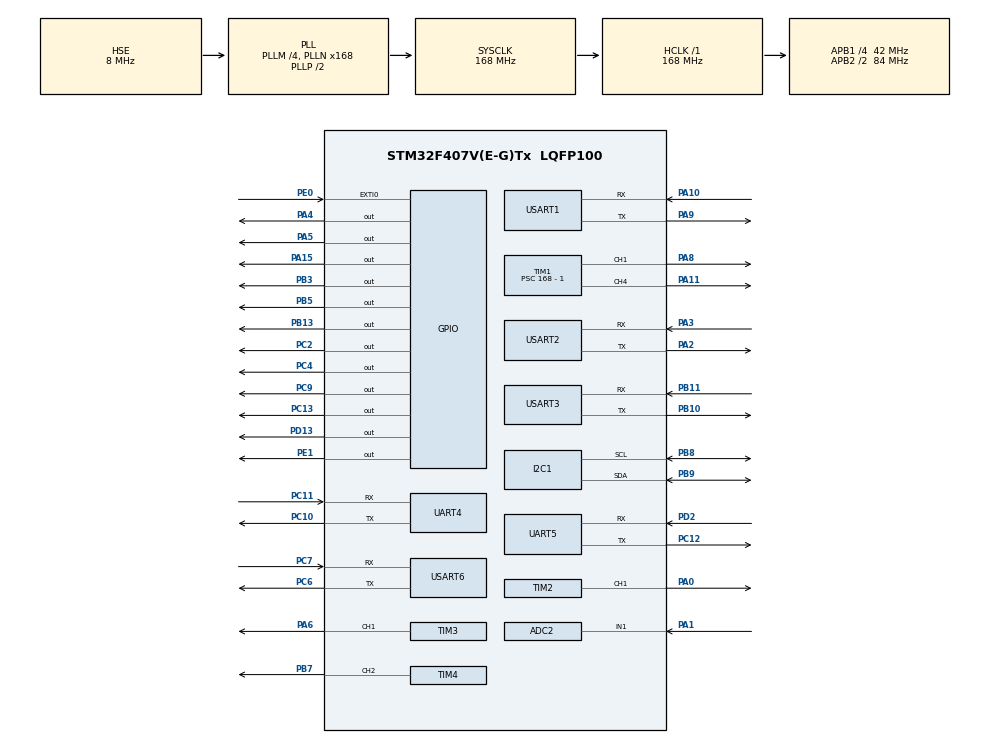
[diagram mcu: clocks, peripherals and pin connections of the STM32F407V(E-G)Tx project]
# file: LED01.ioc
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ADC2.Channel-0\#ChannelRegularConversion=ADC_CHANNEL_1
ADC2.NbrOfConversionFlag=1
ADC2.Rank-0\#ChannelRegularConversion=1
ADC2.SamplingTime-0\#ChannelRegularConversion=ADC_SAMPLETIME_3CYCLES
FREERTOS.BinarySemaphores01=KeySemaphore,Dynamic,NULL,Depleted
FREERTOS.Queues01=LEDQueue,16,LEDMessage*,0,Dynamic,NULL,NULL;CommandQueue,16,uint16_t,0,Dynamic,NULL,NULL;OLEDQueue,16,OLEDMessage*,0,Dynamic,NULL,NULL;TlyQueue,16,TlyMessage,0,Dynamic,NULL,NULL;DeepSensorQueue,16,DeepSensorMessage,0,Dynamic,NULL,NULL
FREERTOS.Tasks01=KeyTask,40,128,StartKeyTask,As weak,NULL,Dynamic,NULL,NULL;LEDTask,16,128,StartLEDTask,As external,NULL,Dynamic,NULL,NULL;CommandTask,41,128,StartCommandTask,As external,NULL,Dynamic,NULL,NULL;OLEDTask,8,256,StartOLEDTask,As external,NULL,Dynamic,NULL,NULL;TlyTask,25,128,StartTlyTask,As external,NULL,Dynamic,NULL,NULL;DeepSensorTask,16,128,StartDeepSensorTask,As external,NULL,Dynamic,NULL,NULL
Mcu.Family=STM32F4
Mcu.Name=STM32F407V(E-G)Tx
Mcu.Package=LQFP100
NVIC.EXTI0_IRQn=true\:5\:0\:false\:false\:true\:true\:true\:true\:true
NVIC.I2C1_ER_IRQn=true\:5\:0\:false\:false\:true\:true\:true\:true\:true
NVIC.I2C1_EV_IRQn=true\:5\:0\:false\:false\:true\:true\:true\:true\:true
NVIC.PriorityGroup=NVIC_PRIORITYGROUP_4
NVIC.TIM6_DAC_IRQn=true\:5\:0\:false\:false\:true\:false\:true\:true\:true
NVIC.TIM7_IRQn=true\:5\:0\:true\:false\:true\:false\:false\:true\:true
NVIC.TimeBase=TIM7_IRQn
NVIC.TimeBaseIP=TIM7
NVIC.UART4_IRQn=true\:5\:0\:false\:false\:true\:true\:true\:true\:true
NVIC.UART5_IRQn=true\:5\:0\:false\:false\:true\:true\:true\:true\:true
NVIC.USART1_IRQn=true\:5\:0\:false\:false\:true\:true\:true\:true\:true
NVIC.USART2_IRQn=true\:5\:0\:false\:false\:true\:true\:true\:true\:true
NVIC.USART3_IRQn=true\:5\:0\:false\:false\:true\:true\:true\:true\:true
NVIC.USART6_IRQn=true\:5\:0\:false\:false\:true\:true\:true\:true\:true
PA0-WKUP.Signal=S_TIM2_CH1_ETR
PA1.Signal=ADCx_IN1
PA10.Mode=Asynchronous
PA10.Signal=USART1_RX
PA11.Signal=S_TIM1_CH4
PA13.Mode=Serial_Wire
PA13.Signal=SYS_JTMS-SWDIO
PA14.Mode=Serial_Wire
PA14.Signal=SYS_JTCK-SWCLK
PA15.Signal=GPIO_Output
PA2.Mode=Asynchronous
PA2.Signal=USART2_TX
PA3.Mode=Asynchronous
PA3.Signal=USART2_RX
PA4.Signal=GPIO_Output
PA5.Signal=GPIO_Output
PA6.Signal=S_TIM3_CH1
PA8.Signal=S_TIM1_CH1
PA9.Mode=Asynchronous
PA9.Signal=USART1_TX
PB10.Mode=Asynchronous
PB10.Signal=USART3_TX
PB11.Mode=Asynchronous
PB11.Signal=USART3_RX
PB13.Signal=GPIO_Output
PB3.Signal=GPIO_Output
PB5.Signal=GPIO_Output
PB7.Signal=S_TIM4_CH2
PB8.Mode=I2C
PB8.Signal=I2C1_SCL
PB9.Mode=I2C
PB9.Signal=I2C1_SDA
PC10.Mode=Asynchronous
PC10.Signal=UART4_TX
PC11.Mode=Asynchronous
PC11.Signal=UART4_RX
PC12.Mode=Asynchronous
PC12.Signal=UART5_TX
PC13-ANTI_TAMP.Signal=GPIO_Output
PC2.Signal=GPIO_Output
PC4.Signal=GPIO_Output
PC6.Mode=Asynchronous
PC6.Signal=USART6_TX
PC7.Mode=Asynchronous
PC7.Signal=USART6_RX
PC9.Signal=GPIO_Output
PD13.Signal=GPIO_Output
PD2.Mode=Asynchronous
PD2.Signal=UART5_RX
PE0.GPIO_ModeDefaultEXTI=GPIO_MODE_IT_FALLING
PE0.Signal=GPXTI0
PE1.Signal=GPIO_Output
PH0-OSC_IN.Mode=HSE-External-Oscillator
PH0-OSC_IN.Signal=RCC_OSC_IN
PH1-OSC_OUT.Mode=HSE-External-Oscillator
PH1-OSC_OUT.Signal=RCC_OSC_OUT
ProjectManager.HeapSize=0x200
ProjectManager.StackSize=0x400
ProjectManager.TargetToolchain=CMake
RCC.48MHZClocksFreq_Value=84000000
RCC.AHBFreq_Value=168000000
RCC.APB1CLKDivider=RCC_HCLK_DIV4
RCC.APB1Freq_Value=42000000
RCC.APB1TimFreq_Value=84000000
RCC.APB2CLKDivider=RCC_HCLK_DIV2
RCC.APB2Freq_Value=84000000
RCC.APB2TimFreq_Value=168000000
RCC.CortexFreq_Value=168000000
RCC.HCLKFreq_Value=168000000
RCC.HSE_VALUE=8000000
RCC.HSI_VALUE=16000000
RCC.LSE_VALUE=32768
RCC.PLLM=4
RCC.PLLN=168
RCC.PLLSourceVirtual=RCC_PLLSOURCE_HSE
RCC.SYSCLKFreq_VALUE=168000000
RCC.SYSCLKSource=RCC_SYSCLKSOURCE_PLLCLK
RCC.VCOOutputFreq_Value=336000000
SH.ADCx_IN1.0=ADC2_IN1,IN1
SH.S_TIM1_CH1.0=TIM1_CH1,PWM Generation1 CH1
SH.S_TIM1_CH4.0=TIM1_CH4,PWM Generation4 CH4
SH.S_TIM2_CH1_ETR.0=TIM2_CH1,PWM Generation1 CH1
SH.S_TIM3_CH1.0=TIM3_CH1,PWM Generation1 CH1
SH.S_TIM4_CH2.0=TIM4_CH2,PWM Generation2 CH2
TIM1.AutoReloadPreload=TIM_AUTORELOAD_PRELOAD_ENABLE
TIM1.Channel-PWM\ Generation1\ CH1=TIM_CHANNEL_1
TIM1.Channel-PWM\ Generation4\ CH4=TIM_CHANNEL_4
TIM1.Period=500 - 1
TIM1.Prescaler=168 - 1
TIM2.AutoReloadPreload=TIM_AUTORELOAD_PRELOAD_ENABLE
TIM2.Channel-PWM\ Generation1\ CH1=TIM_CHANNEL_1
TIM2.Period=500 - 1
TIM2.Prescaler=84 - 1
TIM3.AutoReloadPreload=TIM_AUTORELOAD_PRELOAD_ENABLE
TIM3.Channel-PWM\ Generation1\ CH1=TIM_CHANNEL_1
TIM3.Period=500 - 1
TIM3.Prescaler=84 - 1
TIM4.AutoReloadPreload=TIM_AUTORELOAD_PRELOAD_ENABLE
TIM4.Channel-PWM\ Generation2\ CH2=TIM_CHANNEL_2
TIM4.Period=500 - 1
TIM4.Prescaler=84 - 1
TIM6.AutoReloadPreload=TIM_AUTORELOAD_PRELOAD_ENABLE
TIM6.Period=10000 - 1
TIM6.Prescaler=84 - 1
UART4.VirtualMode=Asynchronous
UART5.VirtualMode=Asynchronous
USART1.VirtualMode=VM_ASYNC
USART2.VirtualMode=VM_ASYNC
USART3.VirtualMode=VM_ASYNC
USART6.VirtualMode=VM_ASYNC
VP_FREERTOS_VS_CMSIS_V2.Mode=CMSIS_V2
VP_SYS_VS_tim7.Mode=TIM7
VP_TIM1_VS_ClockSourceINT.Mode=Internal
VP_TIM2_VS_ClockSourceINT.Mode=Internal
VP_TIM3_VS_ClockSourceINT.Mode=Internal
VP_TIM4_VS_ClockSourceINT.Mode=Internal
VP_TIM6_VS_ClockSourceINT.Mode=Enable_Timer
board=custom

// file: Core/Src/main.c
/* USER CODE BEGIN Header */
/**
  ******************************************************************************
  * @file           : main.c
  * @brief          : Main program body
  ******************************************************************************
  * @attention
  *
  * Copyright (c) 2026 STMicroelectronics.
  * All rights reserved.
  *
  * This software is licensed under terms that can be found in the LICENSE file
  * in the root directory of this software component.
  * If no LICENSE file comes with this software, it is provided AS-IS.
  *
  ******************************************************************************
  */
/* USER CODE END Header */
#include "main.h"
#include "cmsis_os.h"
#include "adc.h"
#include "i2c.h"
#include "tim.h"
#include "usart.h"
#include "gpio.h"

/* USER CODE BEGIN Includes */
#include "system.h"
/* USER CODE END Includes */

void SystemClock_Config(void);
void MX_FREERTOS_Init(void);

int main(void)
{

  /* MCU Configuration--------------------------------------------------------*/

  /* Reset of all peripherals, Initializes the Flash interface and the Systick. */
  HAL_Init();

  /* Configure the system clock */
  SystemClock_Config();

  /* Initialize all configured peripherals */
  MX_GPIO_Init();
  MX_TIM6_Init();
  MX_UART4_Init();
  MX_UART5_Init();
  MX_USART1_UART_Init();
  MX_USART2_UART_Init();
  MX_USART3_UART_Init();
  MX_USART6_UART_Init();
  MX_ADC2_Init();
  MX_TIM1_Init();
  MX_TIM2_Init();
  MX_TIM3_Init();
  MX_TIM4_Init();
  MX_I2C1_Init();

  /* Init scheduler */
  osKernelInitialize();

  /* Call init function for freertos objects (in cmsis_os2.c) */
  MX_FREERTOS_Init();

  /* Start scheduler */
  osKernelStart();

  /* We should never get here as control is now taken by the scheduler */

  /* Infinite loop */
  while (1)
  {

  }
}

void SystemClock_Config(void)
{
  RCC_OscInitTypeDef RCC_OscInitStruct = {0};
  RCC_ClkInitTypeDef RCC_ClkInitStruct = {0};

  /** Configure the main internal regulator output voltage
  */
  __HAL_RCC_PWR_CLK_ENABLE();
  __HAL_PWR_VOLTAGESCALING_CONFIG(PWR_REGULATOR_VOLTAGE_SCALE1);

  /** Initializes the RCC Oscillators according to the specified parameters
  * in the RCC_OscInitTypeDef structure.
  */
  RCC_OscInitStruct.OscillatorType = RCC_OSCILLATORTYPE_HSE;
  RCC_OscInitStruct.HSEState = RCC_HSE_ON;
  RCC_OscInitStruct.PLL.PLLState = RCC_PLL_ON;
  RCC_OscInitStruct.PLL.PLLSource = RCC_PLLSOURCE_HSE;
  RCC_OscInitStruct.PLL.PLLM = 4;
  RCC_OscInitStruct.PLL.PLLN = 168;
  RCC_OscInitStruct.PLL.PLLP = RCC_PLLP_DIV2;
  RCC_OscInitStruct.PLL.PLLQ = 4;
  if (HAL_RCC_OscConfig(&RCC_OscInitStruct) != HAL_OK)
  {
    Error_Handler();
  }

  /** Initializes the CPU, AHB and APB buses clocks
  */
  RCC_ClkInitStruct.ClockType = RCC_CLOCKTYPE_HCLK|RCC_CLOCKTYPE_SYSCLK
                              |RCC_CLOCKTYPE_PCLK1|RCC_CLOCKTYPE_PCLK2;
  RCC_ClkInitStruct.SYSCLKSource = RCC_SYSCLKSOURCE_PLLCLK;
  RCC_ClkInitStruct.AHBCLKDivider = RCC_SYSCLK_DIV1;
  RCC_ClkInitStruct.APB1CLKDivider = RCC_HCLK_DIV4;
  RCC_ClkInitStruct.APB2CLKDivider = RCC_HCLK_DIV2;

  if (HAL_RCC_ClockConfig(&RCC_ClkInitStruct, FLASH_LATENCY_5) != HAL_OK)
  {
    Error_Handler();
  }
}

void HAL_TIM_PeriodElapsedCallback(TIM_HandleTypeDef *htim)
{
  if (htim->Instance == TIM7)
  {
    HAL_IncTick();
  }
}

void Error_Handler(void)
{
  __disable_irq();
  while (1)
  {
  }
}

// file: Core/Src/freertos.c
/* USER CODE BEGIN Header */
/**
  ******************************************************************************
  * File Name          : freertos.c
  * Description        : Code for freertos applications
  ******************************************************************************
  * @attention
  *
  * Copyright (c) 2026 STMicroelectronics.
  * All rights reserved.
  *
  * This software is licensed under terms that can be found in the LICENSE file
  * in the root directory of this software component.
  * If no LICENSE file comes with this software, it is provided AS-IS.
  *
  ******************************************************************************
  */
/* USER CODE END Header */

#include "FreeRTOS.h"
#include "task.h"
#include "main.h"
#include "cmsis_os.h"

/* USER CODE BEGIN Includes */
#include "system.h"
#include "KeyTask.h"
#include "LEDTask.h"
#include "LEDtype.h"
#include "OLEDTask.h"
#include "TlyTask.h"
#include "DeepSensorTask.h"
#include "UART_NVIC.h"  // 包含 Serial_RxPacket 定义
/* USER CODE END Includes */

/* Definitions for KeyTask */
osThreadId_t KeyTaskHandle;
const osThreadAttr_t KeyTask_attributes = {
  .name = "KeyTask",
  .stack_size = 128 * 4,
  .priority = (osPriority_t) osPriorityHigh,
};
/* Definitions for LEDTask */
osThreadId_t LEDTaskHandle;
const osThreadAttr_t LEDTask_attributes = {
  .name = "LEDTask",
  .stack_size = 128 * 4,
  .priority = (osPriority_t) osPriorityBelowNormal,
};
/* Definitions for CommandTask */
osThreadId_t CommandTaskHandle;
const osThreadAttr_t CommandTask_attributes = {
  .name = "CommandTask",
  .stack_size = 128 * 4,
  .priority = (osPriority_t) osPriorityHigh1,
};
/* Definitions for OLEDTask */
osThreadId_t OLEDTaskHandle;
const osThreadAttr_t OLEDTask_attributes = {
  .name = "OLEDTask",
  .stack_size = 256 * 4,
  .priority = (osPriority_t) osPriorityLow,
};
/* Definitions for TlyTask */
osThreadId_t TlyTaskHandle;
const osThreadAttr_t TlyTask_attributes = {
  .name = "TlyTask",
  .stack_size = 128 * 4,
  .priority = (osPriority_t) osPriorityNormal1,
};
/* Definitions for DeepSensorTask */
osThreadId_t DeepSensorTaskHandle;
const osThreadAttr_t DeepSensorTask_attributes = {
  .name = "DeepSensorTask",
  .stack_size = 256 * 4,
  .priority = (osPriority_t) osPriorityBelowNormal,
};
/* Definitions for LEDQueue */
osMessageQueueId_t LEDQueueHandle;
const osMessageQueueAttr_t LEDQueue_attributes = {
  .name = "LEDQueue"
};
/* Definitions for CommandQueue */
osMessageQueueId_t CommandQueueHandle;
const osMessageQueueAttr_t CommandQueue_attributes = {
  .name = "CommandQueue"
};
/* Definitions for OLEDQueue */
osMessageQueueId_t OLEDQueueHandle;
const osMessageQueueAttr_t OLEDQueue_attributes = {
  .name = "OLEDQueue"
};
/* Definitions for TlyQueue */
osMessageQueueId_t TlyQueueHandle;
const osMessageQueueAttr_t TlyQueue_attributes = {
  .name = "TlyQueue"
};
/* Definitions for DeepSensorQueue */
osMessageQueueId_t DeepSensorQueueHandle;
const osMessageQueueAttr_t DeepSensorQueue_attributes = {
  .name = "DeepSensorQueue"
};
/* Definitions for KeySemaphore */
osSemaphoreId_t KeySemaphoreHandle;
const osSemaphoreAttr_t KeySemaphore_attributes = {
  .name = "KeySemaphore"
};

void StartKeyTask(void *argument);
extern void StartLEDTask(void *argument);
extern void StartCommandTask(void *argument);
extern void StartOLEDTask(void *argument);
extern void StartTlyTask(void *argument);
extern void StartDeepSensorTask(void *argument);

void MX_FREERTOS_Init(void); /* (MISRA C 2004 rule 8.1) */

void MX_FREERTOS_Init(void) {

  /* Create the semaphores(s) */
  /* creation of KeySemaphore */
  KeySemaphoreHandle = osSemaphoreNew(1, 0, &KeySemaphore_attributes);

  /* Create the queue(s) */
  /* creation of LEDQueue */
  LEDQueueHandle = osMessageQueueNew (16, sizeof(LEDMessage*), &LEDQueue_attributes);

  /* creation of CommandQueue */
  CommandQueueHandle = osMessageQueueNew (16, sizeof(uint16_t), &CommandQueue_attributes);

  /* creation of OLEDQueue */
  OLEDQueueHandle = osMessageQueueNew (16, sizeof(OLEDMessage*), &OLEDQueue_attributes);

  /* creation of TlyQueue */
  TlyQueueHandle = osMessageQueueNew (16, sizeof(TlyMessage), &TlyQueue_attributes);

  /* creation of DeepSensorQueue */
  DeepSensorQueueHandle = osMessageQueueNew (16, sizeof(DeepSensorMessage), &DeepSensorQueue_attributes);

  /* Create the thread(s) */
  /* creation of KeyTask */
  KeyTaskHandle = osThreadNew(StartKeyTask, NULL, &KeyTask_attributes);

  /* creation of LEDTask */
  LEDTaskHandle = osThreadNew(StartLEDTask, NULL, &LEDTask_attributes);

  /* creation of CommandTask */
  CommandTaskHandle = osThreadNew(StartCommandTask, NULL, &CommandTask_attributes);

  /* creation of OLEDTask */
  OLEDTaskHandle = osThreadNew(StartOLEDTask, NULL, &OLEDTask_attributes);

  /* creation of TlyTask */
  TlyTaskHandle = osThreadNew(StartTlyTask, NULL, &TlyTask_attributes);

  /* creation of DeepSensorTask */
  DeepSensorTaskHandle = osThreadNew(StartDeepSensorTask, NULL, &DeepSensorTask_attributes);

}

__weak void StartKeyTask(void *argument)
{
  for(;;)
  {
    osDelay(1);
  }
}
